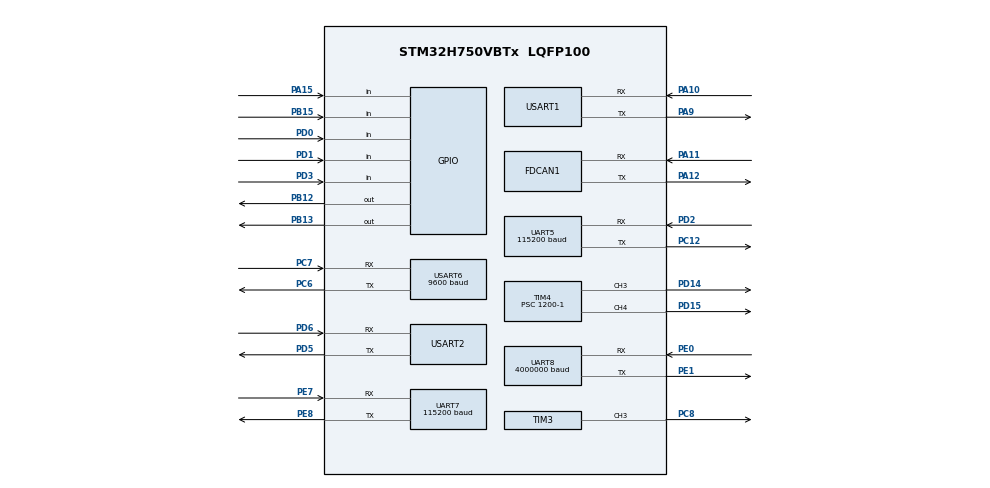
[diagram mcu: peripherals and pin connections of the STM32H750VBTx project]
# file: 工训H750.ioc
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CORTEX_M7.default_mode_Activation=1
Dma.Request0=USART1_RX
Dma.Request1=USART1_TX
Dma.Request2=USART2_RX
Dma.Request3=USART6_RX
Dma.Request4=USART6_TX
Dma.Request5=UART7_RX
Dma.UART7_RX.5.Direction=DMA_PERIPH_TO_MEMORY
Dma.UART7_RX.5.EventEnable=DISABLE
Dma.UART7_RX.5.FIFOMode=DMA_FIFOMODE_DISABLE
Dma.UART7_RX.5.Instance=DMA1_Stream5
Dma.UART7_RX.5.MemDataAlignment=DMA_MDATAALIGN_BYTE
Dma.UART7_RX.5.MemInc=DMA_MINC_ENABLE
Dma.UART7_RX.5.Mode=DMA_NORMAL
Dma.UART7_RX.5.PeriphDataAlignment=DMA_PDATAALIGN_BYTE
Dma.UART7_RX.5.PeriphInc=DMA_PINC_DISABLE
Dma.UART7_RX.5.Polarity=HAL_DMAMUX_REQ_GEN_RISING
Dma.UART7_RX.5.Priority=DMA_PRIORITY_MEDIUM
Dma.UART7_RX.5.RequestNumber=1
Dma.UART7_RX.5.SignalID=NONE
Dma.UART7_RX.5.SyncEnable=DISABLE
Dma.UART7_RX.5.SyncPolarity=HAL_DMAMUX_SYNC_NO_EVENT
Dma.UART7_RX.5.SyncRequestNumber=1
Dma.UART7_RX.5.SyncSignalID=NONE
Dma.USART1_RX.0.Direction=DMA_PERIPH_TO_MEMORY
Dma.USART1_RX.0.EventEnable=DISABLE
Dma.USART1_RX.0.FIFOMode=DMA_FIFOMODE_DISABLE
Dma.USART1_RX.0.Instance=DMA1_Stream0
Dma.USART1_RX.0.MemDataAlignment=DMA_MDATAALIGN_BYTE
Dma.USART1_RX.0.MemInc=DMA_MINC_ENABLE
Dma.USART1_RX.0.Mode=DMA_CIRCULAR
Dma.USART1_RX.0.PeriphDataAlignment=DMA_PDATAALIGN_BYTE
Dma.USART1_RX.0.PeriphInc=DMA_PINC_DISABLE
Dma.USART1_RX.0.Polarity=HAL_DMAMUX_REQ_GEN_RISING
Dma.USART1_RX.0.Priority=DMA_PRIORITY_LOW
Dma.USART1_RX.0.RequestNumber=1
Dma.USART1_RX.0.SignalID=NONE
Dma.USART1_RX.0.SyncEnable=DISABLE
Dma.USART1_RX.0.SyncPolarity=HAL_DMAMUX_SYNC_NO_EVENT
Dma.USART1_RX.0.SyncRequestNumber=1
Dma.USART1_RX.0.SyncSignalID=NONE
Dma.USART1_TX.1.Direction=DMA_MEMORY_TO_PERIPH
Dma.USART1_TX.1.EventEnable=DISABLE
Dma.USART1_TX.1.FIFOMode=DMA_FIFOMODE_DISABLE
Dma.USART1_TX.1.Instance=DMA1_Stream1
Dma.USART1_TX.1.MemDataAlignment=DMA_MDATAALIGN_BYTE
Dma.USART1_TX.1.MemInc=DMA_MINC_ENABLE
Dma.USART1_TX.1.Mode=DMA_NORMAL
Dma.USART1_TX.1.PeriphDataAlignment=DMA_PDATAALIGN_BYTE
Dma.USART1_TX.1.PeriphInc=DMA_PINC_DISABLE
Dma.USART1_TX.1.Polarity=HAL_DMAMUX_REQ_GEN_RISING
Dma.USART1_TX.1.Priority=DMA_PRIORITY_LOW
Dma.USART1_TX.1.RequestNumber=1
Dma.USART1_TX.1.SignalID=NONE
Dma.USART1_TX.1.SyncEnable=DISABLE
Dma.USART1_TX.1.SyncPolarity=HAL_DMAMUX_SYNC_NO_EVENT
Dma.USART1_TX.1.SyncRequestNumber=1
Dma.USART1_TX.1.SyncSignalID=NONE
Dma.USART2_RX.2.Direction=DMA_PERIPH_TO_MEMORY
Dma.USART2_RX.2.EventEnable=DISABLE
Dma.USART2_RX.2.FIFOMode=DMA_FIFOMODE_DISABLE
Dma.USART2_RX.2.Instance=DMA1_Stream2
Dma.USART2_RX.2.MemDataAlignment=DMA_MDATAALIGN_BYTE
Dma.USART2_RX.2.MemInc=DMA_MINC_ENABLE
Dma.USART2_RX.2.Mode=DMA_CIRCULAR
Dma.USART2_RX.2.PeriphDataAlignment=DMA_PDATAALIGN_BYTE
Dma.USART2_RX.2.PeriphInc=DMA_PINC_DISABLE
Dma.USART2_RX.2.Polarity=HAL_DMAMUX_REQ_GEN_RISING
Dma.USART2_RX.2.Priority=DMA_PRIORITY_MEDIUM
Dma.USART2_RX.2.RequestNumber=1
Dma.USART2_RX.2.SignalID=NONE
Dma.USART2_RX.2.SyncEnable=DISABLE
Dma.USART2_RX.2.SyncPolarity=HAL_DMAMUX_SYNC_NO_EVENT
Dma.USART2_RX.2.SyncRequestNumber=1
Dma.USART2_RX.2.SyncSignalID=NONE
Dma.USART6_RX.3.Direction=DMA_PERIPH_TO_MEMORY
Dma.USART6_RX.3.EventEnable=DISABLE
Dma.USART6_RX.3.FIFOMode=DMA_FIFOMODE_DISABLE
Dma.USART6_RX.3.Instance=DMA1_Stream3
Dma.USART6_RX.3.MemDataAlignment=DMA_MDATAALIGN_BYTE
Dma.USART6_RX.3.MemInc=DMA_MINC_ENABLE
Dma.USART6_RX.3.Mode=DMA_NORMAL
Dma.USART6_RX.3.PeriphDataAlignment=DMA_PDATAALIGN_BYTE
Dma.USART6_RX.3.PeriphInc=DMA_PINC_DISABLE
Dma.USART6_RX.3.Polarity=HAL_DMAMUX_REQ_GEN_RISING
Dma.USART6_RX.3.Priority=DMA_PRIORITY_LOW
Dma.USART6_RX.3.RequestNumber=1
Dma.USART6_RX.3.SignalID=NONE
Dma.USART6_RX.3.SyncEnable=DISABLE
Dma.USART6_RX.3.SyncPolarity=HAL_DMAMUX_SYNC_NO_EVENT
Dma.USART6_RX.3.SyncRequestNumber=1
Dma.USART6_RX.3.SyncSignalID=NONE
Dma.USART6_TX.4.Direction=DMA_MEMORY_TO_PERIPH
Dma.USART6_TX.4.EventEnable=DISABLE
Dma.USART6_TX.4.FIFOMode=DMA_FIFOMODE_DISABLE
Dma.USART6_TX.4.Instance=DMA1_Stream4
Dma.USART6_TX.4.MemDataAlignment=DMA_MDATAALIGN_BYTE
Dma.USART6_TX.4.MemInc=DMA_MINC_ENABLE
Dma.USART6_TX.4.Mode=DMA_NORMAL
Dma.USART6_TX.4.PeriphDataAlignment=DMA_PDATAALIGN_BYTE
Dma.USART6_TX.4.PeriphInc=DMA_PINC_DISABLE
Dma.USART6_TX.4.Polarity=HAL_DMAMUX_REQ_GEN_RISING
Dma.USART6_TX.4.Priority=DMA_PRIORITY_LOW
Dma.USART6_TX.4.RequestNumber=1
Dma.USART6_TX.4.SignalID=NONE
Dma.USART6_TX.4.SyncEnable=DISABLE
Dma.USART6_TX.4.SyncPolarity=HAL_DMAMUX_SYNC_NO_EVENT
Dma.USART6_TX.4.SyncRequestNumber=1
Dma.USART6_TX.4.SyncSignalID=NONE
FDCAN1.AutoRetransmission=ENABLE
FDCAN1.CalculateBaudRateNominal=1000000
FDCAN1.CalculateTimeBitNominal=1000
FDCAN1.CalculateTimeQuantumNominal=40.0
FDCAN1.DataPrescaler=1
FDCAN1.DataSyncJumpWidth=5
FDCAN1.DataTimeSeg1=19
FDCAN1.DataTimeSeg2=5
FDCAN1.ExtFiltersNbr=1
FDCAN1.FrameFormat=FDCAN_FRAME_CLASSIC
FDCAN1.Mode=FDCAN_MODE_NORMAL
FDCAN1.NominalPrescaler=1
FDCAN1.NominalSyncJumpWidth=5
FDCAN1.NominalTimeSeg1=19
FDCAN1.NominalTimeSeg2=5
FDCAN1.ProtocolException=DISABLE
FDCAN1.RxBufferSize=FDCAN_DATA_BYTES_8
FDCAN1.RxBuffersNbr=0
FDCAN1.RxFifo0ElmtSize=FDCAN_DATA_BYTES_8
FDCAN1.RxFifo0ElmtsNbr=16
FDCAN1.RxFifo1ElmtSize=FDCAN_DATA_BYTES_8
FDCAN1.RxFifo1ElmtsNbr=0
FDCAN1.StdFiltersNbr=0
FDCAN1.TransmitPause=DISABLE
FDCAN1.TxBuffersNbr=0
FDCAN1.TxElmtSize=FDCAN_DATA_BYTES_8
FDCAN1.TxEventsNbr=0
FDCAN1.TxFifoQueueElmtsNbr=8
FDCAN1.TxFifoQueueMode=FDCAN_TX_FIFO_OPERATION
FREERTOS.INCLUDE_eTaskGetState=1
FREERTOS.INCLUDE_vTaskDelayUntil=1
FREERTOS.Tasks01=IMU_TASK,32,128,IMU_Task,Default,NULL,Dynamic,NULL,NULL;START_TASK,40,256,START_Task,Default,NULL,Dynamic,NULL,NULL;MAIN_TASK,24,512,MAIN_Task,Default,NULL,Dynamic,NULL,NULL;HOST_TASK,16,324,HOST_Task,Default,NULL,Dynamic,NULL,NULL
Mcu.Family=STM32H7
Mcu.Name=STM32H750VBTx
Mcu.Package=LQFP100
NVIC.DMA1_Stream0_IRQn=true\:5\:0\:false\:false\:true\:true\:false\:true\:true
NVIC.DMA1_Stream1_IRQn=true\:5\:0\:false\:false\:true\:true\:false\:true\:true
NVIC.DMA1_Stream2_IRQn=true\:5\:0\:false\:false\:true\:true\:false\:true\:true
NVIC.DMA1_Stream3_IRQn=true\:5\:0\:false\:false\:true\:true\:false\:true\:true
NVIC.DMA1_Stream4_IRQn=true\:5\:0\:false\:false\:true\:true\:false\:true\:true
NVIC.DMA1_Stream5_IRQn=true\:5\:0\:false\:false\:true\:true\:false\:true\:true
NVIC.FDCAN1_IT0_IRQn=true\:5\:0\:false\:false\:true\:true\:true\:true\:true
NVIC.PriorityGroup=NVIC_PRIORITYGROUP_4
NVIC.UART5_IRQn=true\:5\:0\:false\:false\:true\:true\:true\:true\:true
NVIC.UART7_IRQn=true\:5\:0\:false\:false\:true\:true\:true\:true\:true
NVIC.UART8_IRQn=true\:5\:0\:false\:false\:true\:true\:true\:true\:true
NVIC.USART1_IRQn=true\:5\:0\:false\:false\:true\:true\:false\:true\:true
NVIC.USART2_IRQn=true\:5\:0\:false\:false\:true\:true\:true\:true\:true
NVIC.USART6_IRQn=true\:5\:0\:false\:false\:true\:true\:false\:true\:true
PA10.Mode=Asynchronous
PA10.Signal=USART1_RX
PA11.Mode=FDCAN_Activate
PA11.Signal=FDCAN1_RX
PA12.Mode=FDCAN_Activate
PA12.Signal=FDCAN1_TX
PA13\ (JTMS/SWDIO).Mode=Serial_Wire
PA13\ (JTMS/SWDIO).Signal=DEBUG_JTMS-SWDIO
PA14\ (JTCK/SWCLK).Mode=Serial_Wire
PA14\ (JTCK/SWCLK).Signal=DEBUG_JTCK-SWCLK
PA15\ (JTDI).Signal=GPIO_Input
PA9.Mode=Asynchronous
PA9.Signal=USART1_TX
PB12.Signal=GPIO_Output
PB13.Signal=GPIO_Output
PB15.Signal=GPIO_Input
PC12.Mode=Asynchronous
PC12.Signal=UART5_TX
PC6.Mode=Asynchronous
PC6.Signal=USART6_TX
PC7.Mode=Asynchronous
PC7.Signal=USART6_RX
PC8.Signal=S_TIM3_CH3
PD0.Signal=GPIO_Input
PD1.Signal=GPIO_Input
PD14.Signal=S_TIM4_CH3
PD15.Signal=S_TIM4_CH4
PD2.Mode=Asynchronous
PD2.Signal=UART5_RX
PD3.Signal=GPIO_Input
PD5.Mode=Asynchronous
PD5.Signal=USART2_TX
PD6.Mode=Asynchronous
PD6.Signal=USART2_RX
PE0.Mode=Asynchronous
PE0.Signal=UART8_RX
PE1.Mode=Asynchronous
PE1.Signal=UART8_TX
PE7.Mode=Asynchronous
PE7.Signal=UART7_RX
PE8.Mode=Asynchronous
PE8.Signal=UART7_TX
PH0-OSC_IN\ (PH0).Mode=HSE-External-Oscillator
PH0-OSC_IN\ (PH0).Signal=RCC_OSC_IN
PH1-OSC_OUT\ (PH1).Mode=HSE-External-Oscillator
PH1-OSC_OUT\ (PH1).Signal=RCC_OSC_OUT
ProjectManager.HeapSize=0x200
ProjectManager.StackSize=0x400
ProjectManager.TargetToolchain=CMake
RCC.ADCFreq_Value=50390625
RCC.APB1Freq_Value=120000000
RCC.APB2Freq_Value=120000000
RCC.APB3Freq_Value=120000000
RCC.APB4Freq_Value=120000000
RCC.CortexFreq_Value=480000000
RCC.DIVM1=5
RCC.DIVN1=192
RCC.FDCANCLockSelection=RCC_FDCANCLKSOURCE_HSE
RCC.HCLKFreq_Value=120000000
RCC.HPRE=RCC_HCLK_DIV4
RCC.HSE_VALUE=25000000
RCC.HSI_VALUE=64000000
RCC.PLL2FRACN=0
RCC.PLL3FRACN=0
RCC.PLLFRACN=0
RCC.PLLSourceVirtual=RCC_PLLSOURCE_HSE
RCC.SYSCLKFreq_VALUE=480000000
RCC.SYSCLKSource=RCC_SYSCLKSOURCE_PLLCLK
RCC.USBFreq_Value=480000000
SH.S_TIM3_CH3.0=TIM3_CH3,PWM Generation3 CH3
SH.S_TIM4_CH3.0=TIM4_CH3,PWM Generation3 CH3
SH.S_TIM4_CH4.0=TIM4_CH4,PWM Generation4 CH4
TIM3.Channel-PWM\ Generation3\ CH3=TIM_CHANNEL_3
TIM3.Period=2000-1
TIM3.Prescaler=1200-1
TIM4.Channel-PWM\ Generation3\ CH3=TIM_CHANNEL_3
TIM4.Channel-PWM\ Generation4\ CH4=TIM_CHANNEL_4
TIM4.Period=2000-1
TIM4.Prescaler=1200-1
UART5.BaudRate=115200
UART7.BaudRate=115200
UART8.BaudRate=4000000
USART1.VirtualMode-Asynchronous=VM_ASYNC
USART2.VirtualMode-Asynchronous=VM_ASYNC
USART6.BaudRate=9600
USART6.VirtualMode=VM_ASYNC
VP_FREERTOS_VS_CMSIS_V2.Mode=CMSIS_V2
VP_MEMORYMAP_VS_MEMORYMAP.Mode=CurAppReg
board=custom

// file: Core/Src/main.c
/* USER CODE BEGIN Header */
/**
  ******************************************************************************
  * @file           : main.c
  * @brief          : Main program body
  ******************************************************************************
  * @attention
  *
  * Copyright (c) 2026 STMicroelectronics.
  * All rights reserved.
  *
  * This software is licensed under terms that can be found in the LICENSE file
  * in the root directory of this software component.
  * If no LICENSE file comes with this software, it is provided AS-IS.
  *
  ******************************************************************************
  */
/* USER CODE END Header */
#include "main.h"
#include "FreeRTOS.h"
#include "cmsis_os2.h"
#include "dma.h"
#include "fdcan.h"
#include "tim.h"
#include "usart.h"
#include "gpio.h"

void SystemClock_Config(void);
static void MPU_Config(void);
void MX_FREERTOS_Init(void);

int main(void)
{

  /* MPU Configuration--------------------------------------------------------*/
  MPU_Config();

  /* MCU Configuration--------------------------------------------------------*/

  /* Reset of all peripherals, Initializes the Flash interface and the Systick. */
  HAL_Init();

  /* Configure the system clock */
  SystemClock_Config();

  /* Initialize all configured peripherals */
  MX_GPIO_Init();
  MX_DMA_Init();
  MX_UART5_Init();
  MX_UART7_Init();
  MX_UART8_Init();
  MX_USART1_UART_Init();
  MX_USART2_UART_Init();
  MX_USART6_UART_Init();
  MX_FDCAN1_Init();
  MX_TIM4_Init();
  MX_TIM3_Init();

  /* Init scheduler */
  osKernelInitialize();  /* Call init function for freertos objects (in cmsis_os2.c) */
  MX_FREERTOS_Init();

  /* Start scheduler */
  osKernelStart();

  /* We should never get here as control is now taken by the scheduler */

  /* Infinite loop */
  while (1)
  {

  }
}

void SystemClock_Config(void)
{
  RCC_OscInitTypeDef RCC_OscInitStruct = {0};
  RCC_ClkInitTypeDef RCC_ClkInitStruct = {0};

  /** Supply configuration update enable
  */
  HAL_PWREx_ConfigSupply(PWR_LDO_SUPPLY);

  /** Configure the main internal regulator output voltage
  */
  __HAL_PWR_VOLTAGESCALING_CONFIG(PWR_REGULATOR_VOLTAGE_SCALE0);

  while(!__HAL_PWR_GET_FLAG(PWR_FLAG_VOSRDY)) {}

  /** Initializes the RCC Oscillators according to the specified parameters
  * in the RCC_OscInitTypeDef structure.
  */
  RCC_OscInitStruct.OscillatorType = RCC_OSCILLATORTYPE_HSE;
  RCC_OscInitStruct.HSEState = RCC_HSE_ON;
  RCC_OscInitStruct.PLL.PLLState = RCC_PLL_ON;
  RCC_OscInitStruct.PLL.PLLSource = RCC_PLLSOURCE_HSE;
  RCC_OscInitStruct.PLL.PLLM = 5;
  RCC_OscInitStruct.PLL.PLLN = 192;
  RCC_OscInitStruct.PLL.PLLP = 2;
  RCC_OscInitStruct.PLL.PLLQ = 2;
  RCC_OscInitStruct.PLL.PLLR = 2;
  RCC_OscInitStruct.PLL.PLLRGE = RCC_PLL1VCIRANGE_2;
  RCC_OscInitStruct.PLL.PLLVCOSEL = RCC_PLL1VCOWIDE;
  RCC_OscInitStruct.PLL.PLLFRACN = 0;
  if (HAL_RCC_OscConfig(&RCC_OscInitStruct) != HAL_OK)
  {
    Error_Handler();
  }

  /** Initializes the CPU, AHB and APB buses clocks
  */
  RCC_ClkInitStruct.ClockType = RCC_CLOCKTYPE_HCLK|RCC_CLOCKTYPE_SYSCLK
                              |RCC_CLOCKTYPE_PCLK1|RCC_CLOCKTYPE_PCLK2
                              |RCC_CLOCKTYPE_D3PCLK1|RCC_CLOCKTYPE_D1PCLK1;
  RCC_ClkInitStruct.SYSCLKSource = RCC_SYSCLKSOURCE_PLLCLK;
  RCC_ClkInitStruct.SYSCLKDivider = RCC_SYSCLK_DIV1;
  RCC_ClkInitStruct.AHBCLKDivider = RCC_HCLK_DIV4;
  RCC_ClkInitStruct.APB3CLKDivider = RCC_APB3_DIV1;
  RCC_ClkInitStruct.APB1CLKDivider = RCC_APB1_DIV1;
  RCC_ClkInitStruct.APB2CLKDivider = RCC_APB2_DIV1;
  RCC_ClkInitStruct.APB4CLKDivider = RCC_APB4_DIV1;

  if (HAL_RCC_ClockConfig(&RCC_ClkInitStruct, FLASH_LATENCY_1) != HAL_OK)
  {
    Error_Handler();
  }
}

 /* MPU Configuration */

void MPU_Config(void)
{
  MPU_Region_InitTypeDef MPU_InitStruct = {0};

  /* Disables the MPU */
  HAL_MPU_Disable();

  /** Initializes and configures the Region and the memory to be protected
  */
  MPU_InitStruct.Enable = MPU_REGION_ENABLE;
  MPU_InitStruct.Number = MPU_REGION_NUMBER0;
  MPU_InitStruct.BaseAddress = 0x0;
  MPU_InitStruct.Size = MPU_REGION_SIZE_4GB;
  MPU_InitStruct.SubRegionDisable = 0x87;
  MPU_InitStruct.TypeExtField = MPU_TEX_LEVEL0;
  MPU_InitStruct.AccessPermission = MPU_REGION_NO_ACCESS;
  MPU_InitStruct.DisableExec = MPU_INSTRUCTION_ACCESS_DISABLE;
  MPU_InitStruct.IsShareable = MPU_ACCESS_SHAREABLE;
  MPU_InitStruct.IsCacheable = MPU_ACCESS_NOT_CACHEABLE;
  MPU_InitStruct.IsBufferable = MPU_ACCESS_NOT_BUFFERABLE;

  HAL_MPU_ConfigRegion(&MPU_InitStruct);
  /* Enables the MPU */
  HAL_MPU_Enable(MPU_PRIVILEGED_DEFAULT);

}

void Error_Handler(void)
{
  __disable_irq();
  while (1)
  {
  }
}

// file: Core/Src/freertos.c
/* USER CODE BEGIN Header */
/**
  ******************************************************************************
  * File Name          : freertos.c
  * Description        : Code for freertos applications
  ******************************************************************************
  * @attention
  *
  * Copyright (c) 2026 STMicroelectronics.
  * All rights reserved.
  *
  * This software is licensed under terms that can be found in the LICENSE file
  * in the root directory of this software component.
  * If no LICENSE file comes with this software, it is provided AS-IS.
  *
  ******************************************************************************
  */
/* USER CODE END Header */

#include "FreeRTOS.h"
#include "task.h"
#include "main.h"
#include "cmsis_os2.h"

/* USER CODE BEGIN Includes */
#include "control/chassis/chassis.h"
#include "control/heading/heading_control.h"
#include "control/localization/localization_service.h"
#include "control/navigation/navigation.h"
#include "devices/imu/hwt101/hwt101.h"
#include "devices/motor/zdt_x42s/zdt_x42s.h"
#include "platform/communication/host_link.h"
#include "platform/time/dwt_delay.h"

/* USER CODE END Includes */

/* USER CODE BEGIN Variables */
static NavigationRoute s_host_route;

/* USER CODE END Variables */
/* Definitions for IMU_TASK */
osThreadId_t IMU_TASKHandle;
const osThreadAttr_t IMU_TASK_attributes = {
  .name = "IMU_TASK",
  .stack_size = 128 * 4,
  .priority = (osPriority_t) osPriorityAboveNormal,
};
/* Definitions for START_TASK */
osThreadId_t START_TASKHandle;
const osThreadAttr_t START_TASK_attributes = {
  .name = "START_TASK",
  .stack_size = 256 * 4,
  .priority = (osPriority_t) osPriorityHigh,
};
/* Definitions for MAIN_TASK */
osThreadId_t MAIN_TASKHandle;
const osThreadAttr_t MAIN_TASK_attributes = {
  .name = "MAIN_TASK",
  .stack_size = 512 * 4,
  .priority = (osPriority_t) osPriorityNormal,
};
/* Definitions for HOST_TASK */
osThreadId_t HOST_TASKHandle;
const osThreadAttr_t HOST_TASK_attributes = {
  .name = "HOST_TASK",
  .stack_size = 324 * 4,
  .priority = (osPriority_t) osPriorityBelowNormal,
};

void IMU_Task(void *argument);
void START_Task(void *argument);
void MAIN_Task(void *argument);
void HOST_Task(void *argument);

void MX_FREERTOS_Init(void); /* (MISRA C 2004 rule 8.1) */

void MX_FREERTOS_Init(void) {

  /* Create the thread(s) */
  /* creation of IMU_TASK */
  IMU_TASKHandle = osThreadNew(IMU_Task, NULL, &IMU_TASK_attributes);

  /* creation of START_TASK */
  START_TASKHandle = osThreadNew(START_Task, NULL, &START_TASK_attributes);

  /* creation of MAIN_TASK */
  MAIN_TASKHandle = osThreadNew(MAIN_Task, NULL, &MAIN_TASK_attributes);

  /* creation of HOST_TASK */
  HOST_TASKHandle = osThreadNew(HOST_Task, NULL, &HOST_TASK_attributes);

}

/*
 * IMU_Task — 200Hz IMU 数据采集
 *
 * 职责：从 HWT101 环形 DMA 缓冲区中解析角度帧，更新 hwt101_data.yaw。
 * 调用链：IMU_Task → Hwt101_Process()
 *                                  ↓
 *                    Hwt101_Peek() → 校验帧头 0x55
 *                                  → Hwt101_ParseFrame() 校验和 + 解码
 *                                  → 写入 hwt101_data.yaw
 *
 * 输出：hwt101_data.yaw 被 MAIN_Task 读取用于定位积分和航向控制。
 * 周期：5ms（200Hz），匹配 HWT101 的 200Hz 输出率。
 */
void IMU_Task(void *argument)
{
  const uint32_t period_ticks = pdMS_TO_TICKS(5U);
  uint32_t next_wake;

  (void)argument;
  next_wake = osKernelGetTickCount();

  for(;;)
  {
    Hwt101_Process();          /* 解析 DMA 环形缓冲区中的所有完整帧 */
    next_wake += period_ticks;
    (void)osDelayUntil(next_wake);
  }
}

/*
 * START_Task — 一次性初始化任务（启动后自销毁）
 *
 * 职责：按依赖顺序初始化所有子系统，完成后退出释放资源。
 * 初始化顺序：
 *   1. Time_Init()               → 启用 DWT 周期计数器
 *   2. Chassis_Init()            → 启动 FDCAN，配置电机滤波器，发送同步停止
 *      → 内部调用 ZdtX42s_Init() + Chassis_SetWheelSpeedX10({0,0,0,0})
 *   3. Heading_Init()            → 初始化航向 PID，启动 HWT101 DMA
 *      → 内部调用 Pid_Init() + Hwt101_Init()
 *   4. LocalizationService_Init()→ 清零里程计状态，调用 Localization_Init()
 *   5. Navigation_Init()         → 清零导航状态机，置为 IDLE
 *   6. HostLink_Init()           → 启动 USART1 循环 DMA，创建命令队列
 *   7. Chassis_Stop()            → 发送零速确认底盘静止
 *   8. osThreadExit()            → 任务自销毁，释放栈内存
 */
void START_Task(void *argument)
{
  (void)argument;

  if (!Time_Init() ||                          /* DWT 周期计数器 */
      Chassis_Init() != HAL_OK ||              /* FDCAN + 电机驱动 */
      Heading_Init() != HAL_OK)                /* 航向 PID + IMU DMA */
  {
    Error_Handler();
  }
  LocalizationService_Init();                  /* 里程计轮询服务 */
  Navigation_Init();                           /* 导航状态机 */
  if (HostLink_Init() != HAL_OK)               /* 上位机串口协议 */
  {
    Error_Handler();
  }
  (void)Chassis_Stop();                        /* 确认底盘静止 */
  osThreadExit();                              /* 自销毁 */
}

/*
 * MAIN_Task — 200Hz 主控制循环（系统核心）
 *
 * 职责：定位积分、上位机命令分发、健康监测、导航推进、遥测回传。
 * 每个周期执行 5 个阶段，按顺序不可打乱：
 *
 * 阶段1 定位更新：
 *   LocalizationService_Tick()
 *     → 轮询电机位置（ZdtX42s_RequestPosition / ZdtX42s_GetPosition）
 *     → 四轮快照完成后调用 FinishSample() 校验
 *     → Localization_Update() 里程计积分，结合 IMU 偏航角
 *   LocalizationService_GetStatus() → 电机有效性、异常跳变
 *   Localization_GetStatus()        → 定位锚定状态
 *
 * 阶段2 命令处理：
 *   HostLink_TakeCommand() 从队列逐条取出上位机指令
 *   → SET_POSE          → Localization_SetMapPose()    设置地图位姿
 *   → SET_CALIBRATION   → Localization_SetCalibration() 设置轮径/轮距修正
 *   → ROUTE_COMMIT      → Navigation_LoadRoute()       加载路径点序列
 *   → NAV_START         → Navigation_Start()           启动路线跟踪
 *   → NAV_PAUSE         → Navigation_Pause()           暂停运动
 *   → NAV_RESUME        → Navigation_Resume()          恢复运动
 *   → NAV_STOP          → Navigation_Stop()            停止并清除路径
 *   HostLink_CompleteCommand() 回复 ACK/NAK
 *
 * 阶段3 健康监测：
 *   imu_valid       ← Hwt101_GetDiagnostics(): 有效帧>0 且 100ms 内有新帧
 *   can_valid       ← ZdtX42s_GetHealth(): 当前状态非 passive/bus-off 且无异常跳变
 *   heartbeat_valid ← HostLink_GetHeartbeatAgeMs(): 500ms 内有上位机帧
 *   Navigation_SetHealth() → 任一不健康则设置故障标志
 *
 * 阶段4 导航状态机：
 *   Navigation_Tick()
 *     → CheckHealth() 检查四项健康指标，不健康则 Chassis_Stop() + FAULT
 *     → ALIGNING: 原地旋转对齐目标点（Heading_TurnOutput）
 *     → MOVING:   直线行驶 + 航向纠偏（Chassis_SetSpeed）
 *     → 到达判定: 距离 < 10mm 切换下一个路径点
 *
 * 阶段5 状态上报：
 *   HostLink_SendPose()     → 回传位姿 (x, y, yaw)
 *   HostLink_SetStatus()    → 回传健康状态、故障标志、导航状态、当前路径点
 */
void MAIN_Task(void *argument)
{
  const uint32_t period_ticks = pdMS_TO_TICKS(5U);
  uint32_t next_wake = osKernelGetTickCount();

  (void)argument;
  for(;;)
  {
    const uint32_t now_ms = HAL_GetTick();
    const volatile Hwt101Diagnostics *imu_diagnostics = Hwt101_GetDiagnostics();
    LocalizationServiceStatus localization_status;
    ZdtX42sHealth can_health;
    LocalizationStatus pose_status;
    HostCommand command;
    bool imu_valid;
    bool can_valid;
    bool heartbeat_valid;
    NavigationPose pose;

    /* ── 阶段1：定位更新 ── */
    LocalizationService_Tick(now_ms, hwt101_data.yaw);
    localization_status = LocalizationService_GetStatus(now_ms);
    pose_status = Localization_GetStatus();
    ZdtX42s_Service(now_ms);

    /* ── 阶段2：命令处理 ── */
    while (HostLink_TakeCommand(&command))
    {
      NavigationState state = Navigation_GetState();
      bool stopped = state != NAVIGATION_ALIGNING &&
                     state != NAVIGATION_MOVING;
      bool command_success = false;

      switch (command.type)
      {
        case HOST_COMMAND_SET_POSE:
          if (stopped && pose_status.wheel_data_valid &&
              pose_status.imu_data_valid)
          {
            command_success = Localization_SetMapPose(&command.data.pose);
          }
          break;
        case HOST_COMMAND_SET_CALIBRATION:
          if (stopped)
          {
            command_success = Localization_SetCalibration(
                &command.data.calibration);
          }
          break;
        case HOST_COMMAND_ROUTE_COMMIT:
          if (HostLink_TakeCommittedRoute(&s_host_route))
          {
            command_success = Navigation_LoadRoute(&s_host_route) ==
                              NAVIGATION_OK;
          }
          break;
        case HOST_COMMAND_NAV_START:
          if (pose_status.pose_state == LOCALIZATION_ANCHORED)
          {
            command_success = Navigation_Start() == NAVIGATION_OK;
          }
          break;
        case HOST_COMMAND_NAV_PAUSE:
          command_success = state == NAVIGATION_ALIGNING ||
                            state == NAVIGATION_MOVING;
          if (command_success) Navigation_Pause();
          break;
        case HOST_COMMAND_NAV_RESUME:
          command_success = state == NAVIGATION_PAUSED &&
                            Navigation_GetFaultFlags() == 0U;
          if (command_success) Navigation_Resume();
          break;
        case HOST_COMMAND_NAV_STOP:
          Navigation_Stop();
          command_success = true;
          break;
        default:
          break;
      }
      HostLink_CompleteCommand(&command, command_success,
                               command_success ? 0U : 2U);
    }

    /* ── 阶段3：健康监测 ── */
    imu_valid = imu_diagnostics->angle_frame_count != 0U &&
                (now_ms - imu_diagnostics->last_angle_frame_ms) <= 100U;
    can_health = ZdtX42s_GetHealth(now_ms);
    can_valid = can_health.bus_state != ZDT_CAN_ERROR_PASSIVE &&
                can_health.bus_state != ZDT_CAN_BUS_OFF &&
                !localization_status.unreasonable_jump;
    heartbeat_valid = HostLink_GetHeartbeatAgeMs(now_ms) <= 500U;
    Navigation_SetHealth(localization_status.motor_valid_mask == 0x0FU &&
                         can_health.motor_online_mask == 0x0FU,
                         imu_valid, can_valid, heartbeat_valid);

    /* ── 阶段4：导航状态机 ── */
    Navigation_Tick(now_ms);

    /* ── 阶段5：状态上报 ── */
    pose = Localization_GetPose();
    HostLink_SendPose(&pose);
    HostLink_SetStatus(localization_status.motor_valid_mask, imu_valid,
                       Navigation_GetFaultFlags(), Navigation_GetState(),
                       Navigation_GetCurrentWaypoint());
    next_wake += period_ticks;
    (void)osDelayUntil(next_wake);
  }
}

/*
 * HOST_Task — 200Hz 上位机通信处理
 *
 * 职责：处理 USART1 收发，解析上位机协议帧，维护心跳。
 * 调用链：HOST_Task → HostLink_Process()
 *                                  ↓
 *                    解析 RX DMA 环形缓冲区中的协议帧
 *                    → 命令帧：入队到命令队列（供 MAIN_Task 取出）
 *                    → ACK/NAK：推进 TX DMA 发送队列
 *                    → 10Hz 姿态遥测打包
 *
 * 与 MAIN_Task 的分工：
 *   HOST_TASK 负责协议解析和入队（通信层）
 *   MAIN_TASK 负责命令执行和业务逻辑（控制层）
 *   通过 HostLink 内部的命令队列解耦
 */
void HOST_Task(void *argument)
{
  const uint32_t period_ticks = pdMS_TO_TICKS(5U);
  uint32_t next_wake = osKernelGetTickCount();

  (void)argument;
  for(;;)
  {
    HostLink_Process();          /* 解析协议帧、入队命令、发送遥测 */
    next_wake += period_ticks;
    (void)osDelayUntil(next_wake);
  }
}
